AUTOSAR XML (schema 00050)
package /ComponentTypes
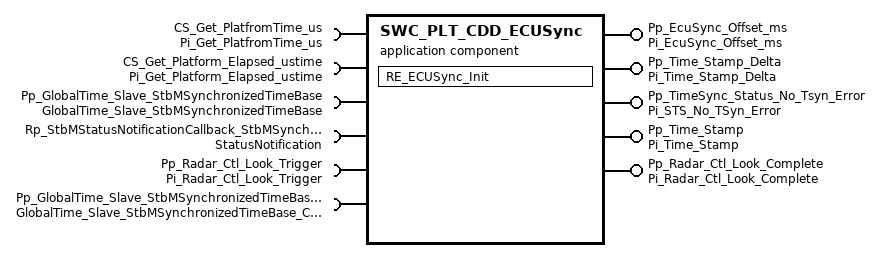
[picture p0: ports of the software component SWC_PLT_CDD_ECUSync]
  application sw component type SWC_PLT_CDD_ECUSync
    provide port Pp_EcuSync_Offset_ms: nonqueued-sender-com-spec{data-element=De_EcuSync_Offset_ms, init-value=0}, provided-interface=Pi_EcuSync_Offset_ms
    provide port Pp_Time_Stamp_Delta: nonqueued-sender-com-spec{data-element=De_Time_Stamp_Delta, init-value=0}, provided-interface=Pi_Time_Stamp_Delta
    provide port Pp_TimeSync_Status_No_Tsyn_Error: nonqueued-sender-com-spec{data-element=De_STS_No_TSyn_Error, init-value=0}, provided-interface=Pi_STS_No_TSyn_Error
    4 x require port:
      CS_Get_PlatfromTime_us: client-com-spec=read, required-interface=Pi_Get_PlatfromTime_us
      CS_Get_Platform_Elapsed_ustime: client-com-spec=read, required-interface=Pi_Get_Platform_Elapsed_ustime
      Pp_GlobalTime_Slave_StbMSynchronizedTimeBase: required-com-specs=[GetTimeBaseStatus, GetTimeLeap, GetRateDeviation, GetCurrentTime, GetSyncTimeRecordHead], required-interface=GlobalTime_Slave_StbMSynchronizedTimeBase
      Rp_StbMStatusNotificationCallback_StbMSynchronizedTimeBase: nonqueued-receiver-com-spec{data-element=eventNotification, filter=data-filter-type=ALWAYS}, required-interface=StatusNotification
    provide port Pp_Time_Stamp: nonqueued-sender-com-spec{data-element=De_StbM_TimeStampType, init-value=fields=[ElementConstant:0, ElementConstant_1:0, ElementConstant_2:0, ElementConstant_3:0]}, provided-interface=Pi_Time_Stamp
    provide port Pp_Radar_Ctl_Look_Complete: provided-interface=Pi_Radar_Ctl_Look_Complete
    require port Pp_Radar_Ctl_Look_Trigger: client-com-spec=Operation, required-interface=Pi_Radar_Ctl_Look_Trigger
    require port Pp_GlobalTime_Slave_StbMSynchronizedTimeBase_CanTsync: required-com-specs=[GetSyncTimeRecordHead, GetTimeBaseStatus, GetTimeLeap, GetRateDeviation, GetCurrentTime], required-interface=GlobalTime_Slave_StbMSynchronizedTimeBase_CanTsync
    behavior SWC_PLT_CDD_ECUSync_InternalBehavior: handle-termination-and-restart=NO-SUPPORT
      init event SWC_PLT_CDD_ECUSync_InitEvent: start-on-event=RE_ECUSync_Init
      runnable RE_ECUSync_Init: external-triggering-point=Pp_Radar_Ctl_Look_Complete.Trigger
        data-receive-point-by-arguments:
          access REC_Rp_StbMStatusNotificationCallback_StbMSynchronizedTimeBase_eventNotification: accessed-variable=Rp_StbMStatusNotificationCallback_StbMSynchronizedTimeBase.eventNotification
        data-send-points:
          4 x access:
            SEND_Pp_EcuSync_Offset_ms_De_EcuSync_Offset_ms: accessed-variable=Pp_EcuSync_Offset_ms.De_EcuSync_Offset_ms
            SEND_Pp_TimeSync_Status_No_Tsyn_Error_De_STS_No_TSyn_Error: accessed-variable=Pp_TimeSync_Status_No_Tsyn_Error.De_STS_No_TSyn_Error
            SEND_Pp_Time_Stamp_De_StbM_TimeStampType: accessed-variable=Pp_Time_Stamp.De_StbM_TimeStampType
            SEND_Pp_Time_Stamp_Delta_De_Time_Stamp_Delta: accessed-variable=Pp_Time_Stamp_Delta.De_Time_Stamp_Delta
        4 x sync call:
          SC_CS_Get_Platform_Elapsed_ustime_read: operation=CS_Get_Platform_Elapsed_ustime.read
          SC_CS_Get_PlatfromTime_us_read: operation=CS_Get_PlatfromTime_us.read
          SC_Pp_GlobalTime_Slave_StbMSynchronizedTimeBase_GetCurrentTime: operation=Pp_GlobalTime_Slave_StbMSynchronizedTimeBase.GetCurrentTime
          SC_Pp_GlobalTime_Slave_StbMSynchronizedTimeBase_CanTsync_GetCurrentTime: operation=Pp_GlobalTime_Slave_StbMSynchronizedTimeBase_CanTsync.GetCurrentTime
        async call AC_Pp_Radar_Ctl_Look_Trigger_Operation: operation=Pp_Radar_Ctl_Look_Trigger.Operation
  swc implementation SWC_PLT_CDD_ECUSync_Implementation: behavior=SWC_PLT_CDD_ECUSync_InternalBehavior
